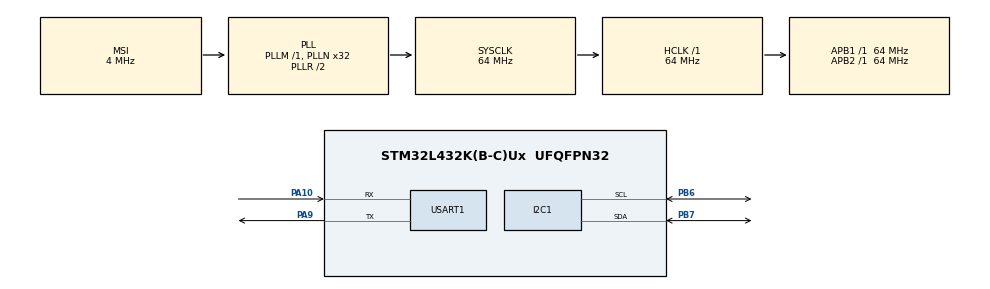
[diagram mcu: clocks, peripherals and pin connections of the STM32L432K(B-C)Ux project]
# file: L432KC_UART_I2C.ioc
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I2C1.Timing=0x10707DBC
Mcu.Family=STM32L4
Mcu.Name=STM32L432K(B-C)Ux
Mcu.Package=UFQFPN32
NVIC.PriorityGroup=NVIC_PRIORITYGROUP_4
PA10.Mode=Asynchronous
PA10.Signal=USART1_RX
PA9.Mode=Asynchronous
PA9.Signal=USART1_TX
PB6.Mode=I2C
PB6.Signal=I2C1_SCL
PB7.Mode=I2C
PB7.Signal=I2C1_SDA
ProjectManager.HeapSize=0x200
ProjectManager.StackSize=0x400
ProjectManager.TargetToolchain=TrueSTUDIO
RCC.ADCFreq_Value=16000000
RCC.AHBFreq_Value=64000000
RCC.APB1Freq_Value=64000000
RCC.APB1TimFreq_Value=64000000
RCC.APB2Freq_Value=64000000
RCC.APB2TimFreq_Value=64000000
RCC.CortexFreq_Value=64000000
RCC.HCLKFreq_Value=64000000
RCC.HSE_VALUE=8000000
RCC.HSI48_VALUE=48000000
RCC.HSI_VALUE=16000000
RCC.LSE_VALUE=32768
RCC.MSI_VALUE=4000000
RCC.PLLN=32
RCC.SYSCLKFreq_VALUE=64000000
RCC.SYSCLKSource=RCC_SYSCLKSOURCE_PLLCLK
RCC.USBFreq_Value=16000000
RCC.VCOOutputFreq_Value=128000000
USART1.VirtualMode-Asynchronous=VM_ASYNC
board=custom

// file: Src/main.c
/**
  ******************************************************************************
  * @file           : main.c
  * @brief          : Main program body
  ******************************************************************************
  ** This notice applies to any and all portions of this file
  * that are not between comment pairs USER CODE BEGIN and
  * USER CODE END. Other portions of this file, whether
  * inserted by the user or by software development tools
  * are owned by their respective copyright owners.
  *
  * COPYRIGHT(c) 2018 STMicroelectronics
  *
  * Redistribution and use in source and binary forms, with or without modification,
  * are permitted provided that the following conditions are met:
  *   1. Redistributions of source code must retain the above copyright notice,
  *      this list of conditions and the following disclaimer.
  *   2. Redistributions in binary form must reproduce the above copyright notice,
  *      this list of conditions and the following disclaimer in the documentation
  *      and/or other materials provided with the distribution.
  *   3. Neither the name of STMicroelectronics nor the names of its contributors
  *      may be used to endorse or promote products derived from this software
  *      without specific prior written permission.
  *
  * THIS SOFTWARE IS PROVIDED BY THE COPYRIGHT HOLDERS AND CONTRIBUTORS "AS IS"
  * AND ANY EXPRESS OR IMPLIED WARRANTIES, INCLUDING, BUT NOT LIMITED TO, THE
  * IMPLIED WARRANTIES OF MERCHANTABILITY AND FITNESS FOR A PARTICULAR PURPOSE ARE
  * DISCLAIMED. IN NO EVENT SHALL THE COPYRIGHT HOLDER OR CONTRIBUTORS BE LIABLE
  * FOR ANY DIRECT, INDIRECT, INCIDENTAL, SPECIAL, EXEMPLARY, OR CONSEQUENTIAL
  * DAMAGES (INCLUDING, BUT NOT LIMITED TO, PROCUREMENT OF SUBSTITUTE GOODS OR
  * SERVICES; LOSS OF USE, DATA, OR PROFITS; OR BUSINESS INTERRUPTION) HOWEVER
  * CAUSED AND ON ANY THEORY OF LIABILITY, WHETHER IN CONTRACT, STRICT LIABILITY,
  * OR TORT (INCLUDING NEGLIGENCE OR OTHERWISE) ARISING IN ANY WAY OUT OF THE USE
  * OF THIS SOFTWARE, EVEN IF ADVISED OF THE POSSIBILITY OF SUCH DAMAGE.
  *
  ******************************************************************************
  */
#include "main.h"
#include "stm32l4xx_hal.h"
#include "string.h"
#include "../UserLibrary/shtx.h"
#include "FloatToString.h"

I2C_HandleTypeDef hi2c1;

UART_HandleTypeDef huart1;

/* USER CODE BEGIN PV */
/* Private variables ---------------------------------------------------------*/

/* USER CODE END PV */

void SystemClock_Config(void);
static void MX_GPIO_Init(void);
static void MX_USART1_UART_Init(void);
static void MX_I2C1_Init(void);

void HS_Serial_UART_Send(char *data, int dataLen);

/* USER CODE BEGIN PFP */
/* Private function prototypes -----------------------------------------------*/

/* USER CODE END PFP */

int main(void)
{
  /* USER CODE BEGIN 1 */
	uint8_t HelloMSG[] = "SHT30 I2C Example";
	char outBuff[50];
	char response_flag;
	float tempC = 0;
	float rHum = 0;
	int count = 0;

  /* USER CODE END 1 */

  /* MCU Configuration----------------------------------------------------------*/

  /* Reset of all peripherals, Initializes the Flash interface and the Systick. */
  HAL_Init();

  /* Configure the system clock */
  SystemClock_Config();

  /* Initialize all configured peripherals */
  MX_GPIO_Init();
  MX_USART1_UART_Init();
  MX_I2C1_Init();
  /* USER CODE BEGIN 2 */

  SHTx_Init(0x45);

  /* USER CODE END 2 */
  /* Welcome Message on Serial Terminal */
   HAL_UART_Transmit(&huart1, HelloMSG, sizeof(HelloMSG), 10);
   memset(outBuff, 0, sizeof(outBuff));
  /* Infinite loop */
  while (1)
  {

  /* USER CODE BEGIN 3 */

	  /* Send data on Serial terminal  */
	 sprintf(outBuff, "\r\nCount: %d", count++);
	 HS_Serial_UART_Send(outBuff, strlen(outBuff));

	 HAL_GPIO_TogglePin(GPIOB, GPIO_PIN_3);

	 HAL_Delay(1000);

	 if(SHTx_Read(&hi2c1, &tempC, &rHum))
	 {
		 /* Send Humidity over UART terminal */
		 dtostrf(tempC, 4, 2, outBuff);
		 HS_Serial_UART_Send(", Temp:", strlen(", Temp:"));
		 HS_Serial_UART_Send(outBuff, strlen(outBuff));

		 /* Send Humidity over UART terminal */
		 dtostrf(rHum, 4, 2, outBuff);
		 HS_Serial_UART_Send(", RH:", strlen(", RH:"));
		 HS_Serial_UART_Send(outBuff, strlen(outBuff));
	 }
	 else
	 {
		 HS_Serial_UART_Send(", SHTx failed\r\n", strlen(", SHTx failed\r\n"));
	 }

  }
  /* USER CODE END 3 */

}

/* UART Function for Sending over PC Terminal */
void HS_Serial_UART_Send(char *data, int dataLen)
{
	HAL_UART_Transmit(&huart1, (uint8_t *)data, dataLen, 10);
}

void SystemClock_Config(void)
{

  RCC_OscInitTypeDef RCC_OscInitStruct;
  RCC_ClkInitTypeDef RCC_ClkInitStruct;
  RCC_PeriphCLKInitTypeDef PeriphClkInit;

    /**Initializes the CPU, AHB and APB busses clocks
    */
  RCC_OscInitStruct.OscillatorType = RCC_OSCILLATORTYPE_MSI;
  RCC_OscInitStruct.MSIState = RCC_MSI_ON;
  RCC_OscInitStruct.MSICalibrationValue = 0;
  RCC_OscInitStruct.MSIClockRange = RCC_MSIRANGE_6;
  RCC_OscInitStruct.PLL.PLLState = RCC_PLL_ON;
  RCC_OscInitStruct.PLL.PLLSource = RCC_PLLSOURCE_MSI;
  RCC_OscInitStruct.PLL.PLLM = 1;
  RCC_OscInitStruct.PLL.PLLN = 32;
  RCC_OscInitStruct.PLL.PLLP = RCC_PLLP_DIV7;
  RCC_OscInitStruct.PLL.PLLQ = RCC_PLLQ_DIV2;
  RCC_OscInitStruct.PLL.PLLR = RCC_PLLR_DIV2;
  if (HAL_RCC_OscConfig(&RCC_OscInitStruct) != HAL_OK)
  {
    _Error_Handler(__FILE__, __LINE__);
  }

    /**Initializes the CPU, AHB and APB busses clocks
    */
  RCC_ClkInitStruct.ClockType = RCC_CLOCKTYPE_HCLK|RCC_CLOCKTYPE_SYSCLK
                              |RCC_CLOCKTYPE_PCLK1|RCC_CLOCKTYPE_PCLK2;
  RCC_ClkInitStruct.SYSCLKSource = RCC_SYSCLKSOURCE_PLLCLK;
  RCC_ClkInitStruct.AHBCLKDivider = RCC_SYSCLK_DIV1;
  RCC_ClkInitStruct.APB1CLKDivider = RCC_HCLK_DIV1;
  RCC_ClkInitStruct.APB2CLKDivider = RCC_HCLK_DIV1;

  if (HAL_RCC_ClockConfig(&RCC_ClkInitStruct, FLASH_LATENCY_3) != HAL_OK)
  {
    _Error_Handler(__FILE__, __LINE__);
  }

  PeriphClkInit.PeriphClockSelection = RCC_PERIPHCLK_USART1|RCC_PERIPHCLK_I2C1;
  PeriphClkInit.Usart1ClockSelection = RCC_USART1CLKSOURCE_PCLK2;
  PeriphClkInit.I2c1ClockSelection = RCC_I2C1CLKSOURCE_PCLK1;
  if (HAL_RCCEx_PeriphCLKConfig(&PeriphClkInit) != HAL_OK)
  {
    _Error_Handler(__FILE__, __LINE__);
  }

    /**Configure the main internal regulator output voltage
    */
  if (HAL_PWREx_ControlVoltageScaling(PWR_REGULATOR_VOLTAGE_SCALE1) != HAL_OK)
  {
    _Error_Handler(__FILE__, __LINE__);
  }

    /**Configure the Systick interrupt time
    */
  HAL_SYSTICK_Config(HAL_RCC_GetHCLKFreq()/1000);

    /**Configure the Systick
    */
  HAL_SYSTICK_CLKSourceConfig(SYSTICK_CLKSOURCE_HCLK);

  /* SysTick_IRQn interrupt configuration */
  HAL_NVIC_SetPriority(SysTick_IRQn, 0, 0);
}

/* I2C1 init function */
static void MX_I2C1_Init(void)
{

  hi2c1.Instance = I2C1;
  hi2c1.Init.Timing = 0x10707DBC;
  hi2c1.Init.OwnAddress1 = 0;
  hi2c1.Init.AddressingMode = I2C_ADDRESSINGMODE_7BIT;
  hi2c1.Init.DualAddressMode = I2C_DUALADDRESS_DISABLE;
  hi2c1.Init.OwnAddress2 = 0;
  hi2c1.Init.OwnAddress2Masks = I2C_OA2_NOMASK;
  hi2c1.Init.GeneralCallMode = I2C_GENERALCALL_DISABLE;
  hi2c1.Init.NoStretchMode = I2C_NOSTRETCH_DISABLE;
  if (HAL_I2C_Init(&hi2c1) != HAL_OK)
  {
    _Error_Handler(__FILE__, __LINE__);
  }

    /**Configure Analogue filter
    */
  if (HAL_I2CEx_ConfigAnalogFilter(&hi2c1, I2C_ANALOGFILTER_ENABLE) != HAL_OK)
  {
    _Error_Handler(__FILE__, __LINE__);
  }

    /**Configure Digital filter
    */
  if (HAL_I2CEx_ConfigDigitalFilter(&hi2c1, 0) != HAL_OK)
  {
    _Error_Handler(__FILE__, __LINE__);
  }

}

/* USART1 init function */
static void MX_USART1_UART_Init(void)
{

  huart1.Instance = USART1;
  huart1.Init.BaudRate = 115200;
  huart1.Init.WordLength = UART_WORDLENGTH_8B;
  huart1.Init.StopBits = UART_STOPBITS_1;
  huart1.Init.Parity = UART_PARITY_NONE;
  huart1.Init.Mode = UART_MODE_TX_RX;
  huart1.Init.HwFlowCtl = UART_HWCONTROL_NONE;
  huart1.Init.OverSampling = UART_OVERSAMPLING_16;
  huart1.Init.OneBitSampling = UART_ONE_BIT_SAMPLE_DISABLE;
  huart1.AdvancedInit.AdvFeatureInit = UART_ADVFEATURE_NO_INIT;
  if (HAL_UART_Init(&huart1) != HAL_OK)
  {
    _Error_Handler(__FILE__, __LINE__);
  }

}

/* Pinout Configuration
    Configure pins as
        * Analog
        * Input
        * Output
        * EVENT_OUT
        * EXTI
*/
static void MX_GPIO_Init(void)
{

  GPIO_InitTypeDef GPIO_InitStruct;

  /* GPIO Ports Clock Enable */
  /* GPIO Ports Clock Enable */
  __HAL_RCC_GPIOA_CLK_ENABLE();
  __HAL_RCC_GPIOB_CLK_ENABLE();

  /*Configure GPIO pin Output Level */
  HAL_GPIO_WritePin(GPIOB, GPIO_PIN_3, GPIO_PIN_RESET);

  /*Configure GPIO pin : PB3 */
  GPIO_InitStruct.Pin = GPIO_PIN_3;
  GPIO_InitStruct.Mode = GPIO_MODE_OUTPUT_PP;
  GPIO_InitStruct.Pull = GPIO_NOPULL;
  GPIO_InitStruct.Speed = GPIO_SPEED_FREQ_LOW;
  HAL_GPIO_Init(GPIOB, &GPIO_InitStruct);

}
/* USER CODE END 4 */

void _Error_Handler(char *file, int line)
{
  while(1)
  {
  }
}

/************************ (C) COPYRIGHT STMicroelectronics *****END OF FILE****/
